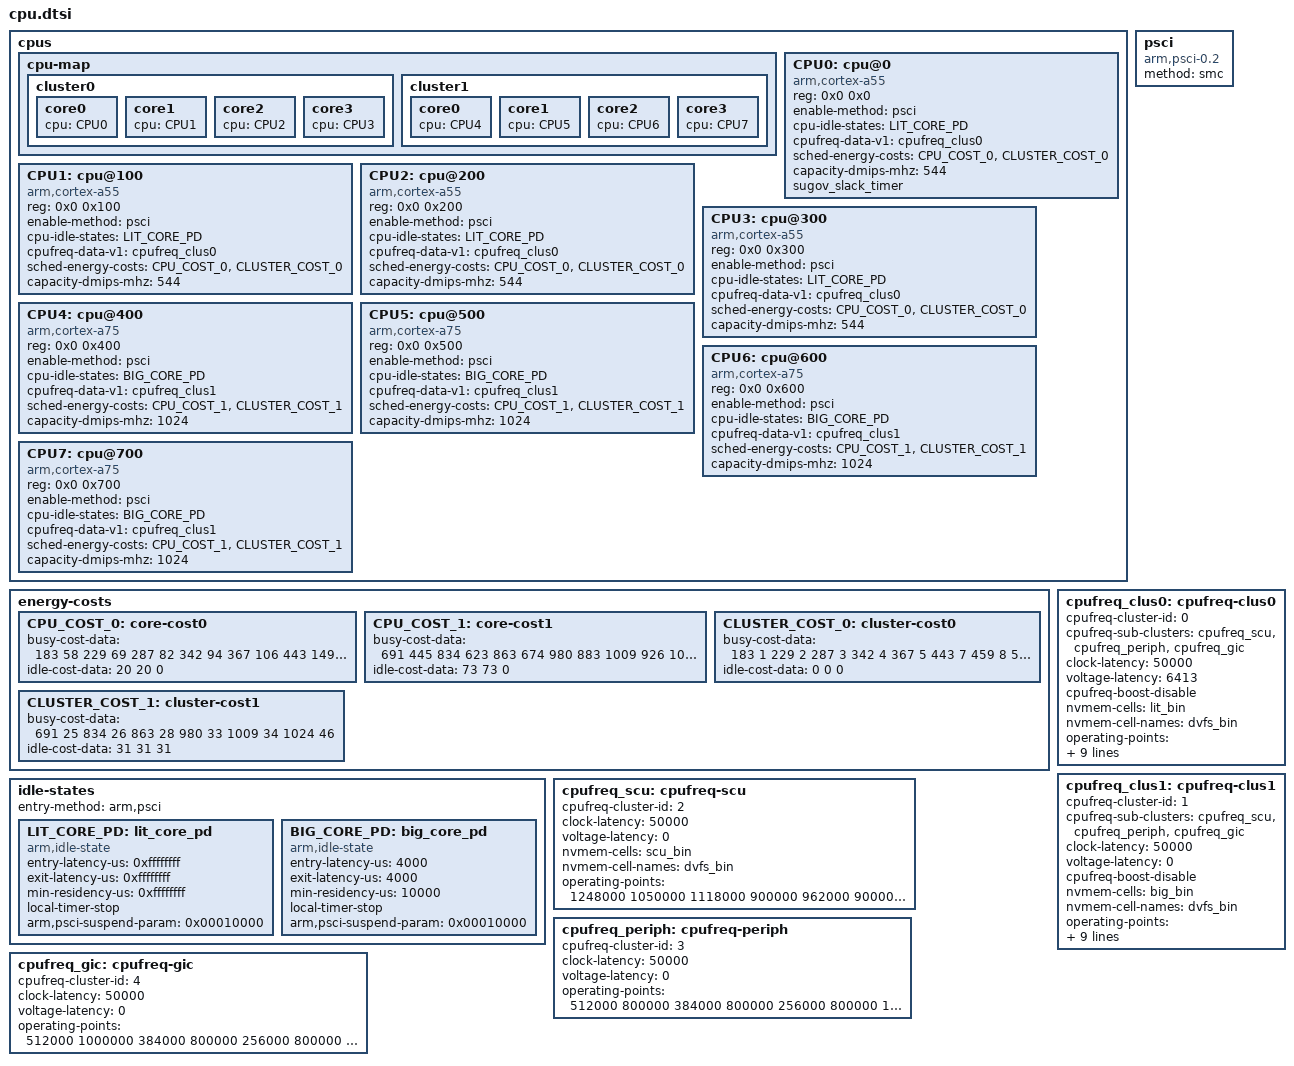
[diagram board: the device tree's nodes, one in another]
/*
 * Spreadtrum Roc1 SoC DTS file
 *
 * Copyright (C) 2018, Spreadtrum Communications Inc.
 *
 * This file is licensed under a dual GPLv2 or X11 license.
 */

	cpus {
		#address-cells = <2>;
		#size-cells = <0>;

		cpu-map {
			cluster0 {
				core0 {
					cpu = <&CPU0>;
				};
				core1 {
					cpu = <&CPU1>;
				};
				core2 {
					cpu = <&CPU2>;
				};
				core3 {
					cpu = <&CPU3>;
				};
			};
			cluster1 {
				core0 {
					cpu = <&CPU4>;
				};
				core1 {
					cpu = <&CPU5>;
				};
				core2 {
					cpu = <&CPU6>;
				};
				core3 {
					cpu = <&CPU7>;
				};
			};
		};

		CPU0: cpu@0 {
			device_type = "cpu";
			compatible = "arm,cortex-a55","arm,armv8";
			reg = <0x0 0x0>;
			enable-method = "psci";
			cpu-idle-states = <&LIT_CORE_PD>;
			cpufreq-data-v1 = <&cpufreq_clus0>;
			sched-energy-costs = <&CPU_COST_0 &CLUSTER_COST_0>;
			capacity-dmips-mhz = <544>;
			sugov_slack_timer;
		};
		CPU1: cpu@100 {
			device_type = "cpu";
			compatible = "arm,cortex-a55","arm,armv8";
			reg = <0x0 0x100>;
			enable-method = "psci";
			cpu-idle-states = <&LIT_CORE_PD>;
			cpufreq-data-v1 = <&cpufreq_clus0>;
			sched-energy-costs = <&CPU_COST_0 &CLUSTER_COST_0>;
			capacity-dmips-mhz = <544>;
		};
		CPU2: cpu@200 {
			device_type = "cpu";
			compatible = "arm,cortex-a55","arm,armv8";
			reg = <0x0 0x200>;
			enable-method = "psci";
			cpu-idle-states = <&LIT_CORE_PD>;
			cpufreq-data-v1 = <&cpufreq_clus0>;
			sched-energy-costs = <&CPU_COST_0 &CLUSTER_COST_0>;
			capacity-dmips-mhz = <544>;
		};
		CPU3: cpu@300 {
			device_type = "cpu";
			compatible = "arm,cortex-a55","arm,armv8";
			reg = <0x0 0x300>;
			enable-method = "psci";
			cpu-idle-states = <&LIT_CORE_PD>;
			cpufreq-data-v1 = <&cpufreq_clus0>;
			sched-energy-costs = <&CPU_COST_0 &CLUSTER_COST_0>;
			capacity-dmips-mhz = <544>;
		};
		CPU4: cpu@400 {
			device_type = "cpu";
			compatible = "arm,cortex-a75","arm,armv8";
			reg = <0x0 0x400>;
			enable-method = "psci";
			cpu-idle-states = <&BIG_CORE_PD>;
			cpufreq-data-v1 = <&cpufreq_clus1>;
			sched-energy-costs = <&CPU_COST_1 &CLUSTER_COST_1>;
			capacity-dmips-mhz = <1024>;
		};
		CPU5: cpu@500 {
			device_type = "cpu";
			compatible = "arm,cortex-a75","arm,armv8";
			reg = <0x0 0x500>;
			enable-method = "psci";
			cpu-idle-states = <&BIG_CORE_PD>;
			cpufreq-data-v1 = <&cpufreq_clus1>;
			sched-energy-costs = <&CPU_COST_1 &CLUSTER_COST_1>;
			capacity-dmips-mhz = <1024>;
		};
		CPU6: cpu@600 {
			device_type = "cpu";
			compatible = "arm,cortex-a75","arm,armv8";
			reg = <0x0 0x600>;
			enable-method = "psci";
			cpu-idle-states = <&BIG_CORE_PD>;
			cpufreq-data-v1 = <&cpufreq_clus1>;
			sched-energy-costs = <&CPU_COST_1 &CLUSTER_COST_1>;
			capacity-dmips-mhz = <1024>;
		};
		CPU7: cpu@700 {
			device_type = "cpu";
			compatible = "arm,cortex-a75","arm,armv8";
			reg = <0x0 0x700>;
			enable-method = "psci";
			cpu-idle-states = <&BIG_CORE_PD>;
			cpufreq-data-v1 = <&cpufreq_clus1>;
			sched-energy-costs = <&CPU_COST_1 &CLUSTER_COST_1>;
			capacity-dmips-mhz = <1024>;
		};
	};

	energy-costs {
		CPU_COST_0: core-cost0 {
			busy-cost-data = <
				183	58		//614MHz
				229	69		//768MHz
				287	82		//962MHz
				342	94		//1144MHZ
				367	106		//1229MHz
				443	149		//1482MHz
				459	159		//1534MHz
				513	198		//1716MHz
				544	223		//1820MHz
			>;
			idle-cost-data = <
				20		/* ACTIVE-IDLE */
				20		/* WFI */
				0		/* CORE_PD */
			>;
		};
		CPU_COST_1: core-cost1 {
			busy-cost-data = <
				691	445		//1229MHz
				834	623		//1482MHz
				863	674		//1534MHz
				980	883		//1742MHz
				1009	926		//1794MHz
				1024	959		//1820MHz
			>;
			idle-cost-data = <
				73		/* ACTIVE-IDLE */
				73		/* WFI */
				0		/* CORE_PD */
			>;
		};
		CLUSTER_COST_0: cluster-cost0 {
			busy-cost-data = <
				183	1		//614MHz
				229	2		//768MHz
				287	3		//962MHz
				342	4		//1144MHz
				367	5		//1229MHz
				443	7		//1482MHz
				459	8		//1534MHz
				513	9		//1716MHz
				544	10		//1820MHz
			>;
			idle-cost-data = <
				0		/* ACTIVE-IDLE */
				0		/* WFI */
				0		/* CORE_PD */
			>;
		};
		CLUSTER_COST_1: cluster-cost1 {
			busy-cost-data = <
				691	25		//1229MHz
				834	26		//1482MHz
				863	28		//1534MHz
				980	33		//1742MHz
				1009	34		//1794MHz
				1024	46		//1820MHz
			>;
			idle-cost-data = <
				31		/* ACTIVE-IDLE */
				31		/* WFI */
				31		/* CORE_PD */
			>;
		};
	};

	idle-states {
		entry-method = "arm,psci";
		LIT_CORE_PD: lit_core_pd {
			compatible = "arm,idle-state";
			entry-latency-us = <0xffffffff>;
			exit-latency-us = <0xffffffff>;
			min-residency-us = <0xffffffff>;
			local-timer-stop;
			arm,psci-suspend-param = <0x00010000>;
		};
		BIG_CORE_PD: big_core_pd {
			compatible = "arm,idle-state";
			entry-latency-us = <4000>;
			exit-latency-us = <4000>;
			min-residency-us = <10000>;
			local-timer-stop;
			arm,psci-suspend-param = <0x00010000>;
		};
	};

	psci {
		compatible = "arm,psci-0.2";
		method = "smc";
	};

	cpufreq_clus0: cpufreq-clus0 {
		cpufreq-cluster-id = <0>;
		cpufreq-sub-clusters =  <&cpufreq_scu>,
					<&cpufreq_periph>,
					<&cpufreq_gic>;
		clock-latency = <50000>;
		voltage-latency = <6413>;
		cpufreq-boost-disable;
		nvmem-cells = <&lit_bin>;
		nvmem-cell-names = "dvfs_bin";

		operating-points = <
			/*kHZ	uV*/
			1820000 1000000
			1716000 996875
			1534000 937500
			1482000 921875
			1228800 843750
			1144000 815625
			962000  759375
			768000  750000
			614400  750000
		>;

		operating-points-1 = <
			/*kHZ	uV*/
			1820000 928125
			1716000 896875
			1534000 843750
			1482000 828125
			1228800 753125
			1144000 750000
			962000  750000
			768000  750000
			614400  750000
		>;

		operating-points-2 = <
			/*kHZ	uV*/
			1820000 959375
			1716000 928125
			1534000 871875
			1482000 856250
			1228800 778125
			1144000 753125
			962000  750000
			768000  750000
			614400  750000
		>;

		operating-points-3 = <
			/*kHZ	uV*/
			1820000 981250
			1716000 950000
			1534000 893750
			1482000 878125
			1228800 800000
			1144000 775000
			962000  750000
			768000  750000
			614400  750000
		>;

		operating-points-4 = <
			/*kHZ	uV*/
			1820000 1000000
			1716000 996875
			1534000 937500
			1482000 921875
			1228800 843750
			1144000 815625
			962000  759375
			768000  750000
			614400  750000
		>;

	};

	cpufreq_clus1: cpufreq-clus1 {
		cpufreq-cluster-id = <1>;
		cpufreq-sub-clusters =  <&cpufreq_scu>,
					<&cpufreq_periph>,
					<&cpufreq_gic>;
		clock-latency = <50000>;
		voltage-latency = <0>;
		cpufreq-boost-disable;
		nvmem-cells = <&big_bin>;
		nvmem-cell-names = "dvfs_bin";

		operating-points = <
			/*kHZ	uV*/
			1820000 1000000
			1794000 990000
			1742000 980000
			1534000 920000
			1482000 900000
			1228800 830000
		>;
		operating-points-1 = <
			/*kHZ	uV*/
			1820000 900000
			1794000 890000
			1742000 870000
			1534000 800000
			1482000 780000
			1228800 750000
		>;
		operating-points-2 = <
			/*kHZ	uV*/
			1820000 930000
			1794000 920000
			1742000 910000
			1534000 840000
			1482000 820000
			1228800 750000
		>;
		operating-points-3 = <
			/*kHZ	uV*/
			1820000 950000
			1794000 940000
			1742000 930000
			1534000 860000
			1482000 840000
			1228800 760000
		>;
		operating-points-4 = <
			/*kHZ	uV*/
			1820000 1000000
			1794000 990000
			1742000 980000
			1534000 920000
			1482000 900000
			1228800 830000
		>;
	};

	cpufreq_scu: cpufreq-scu {
		cpufreq-cluster-id = <2>;
		clock-latency = <50000>;
		voltage-latency = <0>;
		nvmem-cells = <&scu_bin>;
		nvmem-cell-names = "dvfs_bin";

		operating-points = <
			/*kHZ	uV*/
			1248000 1050000
			1118000 900000
			962000  900000
			858000  800000
			768000  800000
			650000  750000
			520000  750000
		>;
	};

	cpufreq_periph: cpufreq-periph {
		cpufreq-cluster-id = <3>;
		clock-latency = <50000>;
		voltage-latency = <0>;
		operating-points = <
			/*kHZ	uV*/
			512000 800000
			384000 800000
			256000 800000
			153600 750000
		>;
	};

	cpufreq_gic: cpufreq-gic {
		cpufreq-cluster-id = <4>;
		clock-latency = <50000>;
		voltage-latency = <0>;
		operating-points = <
			/*kHZ	uV*/
			512000 1000000
			384000 800000
			256000 800000
			192000 800000
			153600 750000
		>;
	};

